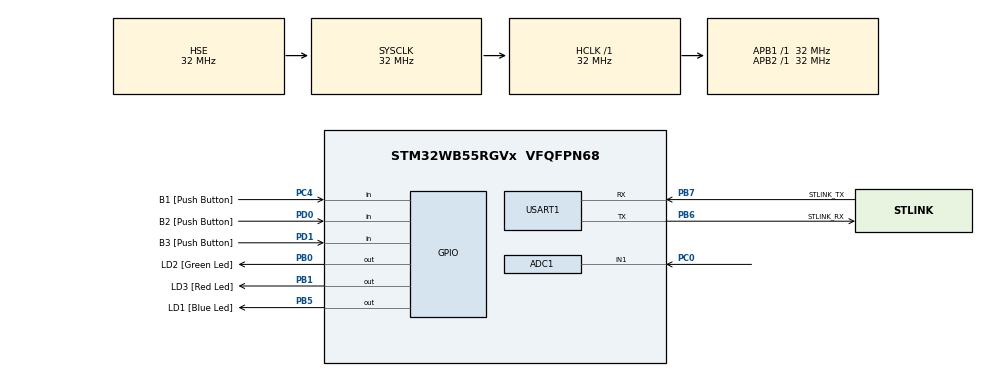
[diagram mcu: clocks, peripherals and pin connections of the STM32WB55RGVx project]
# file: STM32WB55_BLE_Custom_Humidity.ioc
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ADC1.Channel-0\#ChannelRegularConversion=ADC_CHANNEL_1
ADC1.NbrOfConversionFlag=1
ADC1.OffsetNumber-0\#ChannelRegularConversion=ADC_OFFSET_NONE
ADC1.Rank-0\#ChannelRegularConversion=1
ADC1.SamplingTime-0\#ChannelRegularConversion=ADC_SAMPLETIME_2CYCLES_5
ADC1.master=1
Mcu.Family=STM32WB
Mcu.Name=STM32WB55RGVx
Mcu.Package=VFQFPN68
NVIC.ADC1_IRQn=true\:0\:0\:false\:false\:true\:true\:true\:true
NVIC.HSEM_IRQn=true\:0\:0\:false\:false\:true\:false\:true\:true
NVIC.IPCC_C1_RX_IRQn=true\:0\:0\:false\:false\:true\:true\:true\:true
NVIC.IPCC_C1_TX_IRQn=true\:0\:0\:false\:false\:true\:true\:true\:true
NVIC.PriorityGroup=NVIC_PRIORITYGROUP_4
NVIC.RTC_WKUP_IRQn=true\:0\:0\:false\:false\:true\:true\:true\:true
NVIC.TIM1_UP_TIM16_IRQn=true\:0\:0\:false\:false\:true\:true\:true\:true
OSC_IN.Mode=HSE-External-Oscillator
OSC_IN.Signal=RCC_OSC_IN
OSC_OUT.Mode=HSE-External-Oscillator
OSC_OUT.Signal=RCC_OSC_OUT
PA11.Signal=USB_DM
PA12.Signal=USB_DP
PA13.GPIO_Label=JTMS
PA13.Mode=Trace_Asynchronous_SW
PA13.Signal=SYS_JTMS-SWDIO
PA14.GPIO_Label=JTCK
PA14.Mode=Trace_Asynchronous_SW
PA14.Signal=SYS_JTCK-SWCLK
PB0.GPIO_Label=LD2 [Green Led]
PB0.Signal=GPIO_Output
PB1.GPIO_Label=LD3 [Red Led]
PB1.Signal=GPIO_Output
PB3.GPIO_Label=JTDO
PB3.Mode=Trace_Asynchronous_SW
PB3.Signal=SYS_JTDO-SWO
PB5.GPIO_Label=LD1 [Blue Led]
PB5.Signal=GPIO_Output
PB6.GPIO_Label=STLINK_RX
PB6.GPIO_PuPd=GPIO_PULLUP
PB6.Mode=Asynchronous
PB6.Signal=USART1_TX
PB7.GPIO_Label=STLINK_TX
PB7.GPIO_PuPd=GPIO_PULLUP
PB7.Mode=Asynchronous
PB7.Signal=USART1_RX
PC0.Signal=ADCx_IN1
PC13.Mode=SYS_WakeUp1
PC13.Signal=SYS_WKUP2
PC14-OSC32_IN.Mode=LSE-External-Oscillator
PC14-OSC32_IN.Signal=RCC_OSC32_IN
PC15-OSC32_OUT.Mode=LSE-External-Oscillator
PC15-OSC32_OUT.Signal=RCC_OSC32_OUT
PC4.GPIO_Label=B1 [Push Button]
PC4.Signal=GPIO_Input
PD0.GPIO_Label=B2 [Push Button]
PD0.Signal=GPIO_Input
PD1.GPIO_Label=B3 [Push Button]
PD1.Signal=GPIO_Input
ProjectManager.HeapSize=0x400
ProjectManager.StackSize=0x1000
ProjectManager.TargetToolchain=STM32CubeIDE
RCC.ADCFreq_Value=48000000
RCC.AHBFreq_Value=32000000
RCC.APB1Freq_Value=32000000
RCC.APB1TimFreq_Value=32000000
RCC.APB2Freq_Value=32000000
RCC.APB2TimFreq_Value=32000000
RCC.APB3Freq_Value=16000000
RCC.CortexFreq_Value=32000000
RCC.HCLKFreq_Value=32000000
RCC.HSE_VALUE=32000000
RCC.HSI48_VALUE=48000000
RCC.HSI_VALUE=16000000
RCC.LSE_Drive_Capability=RCC_LSEDRIVE_LOW
RCC.PLLN=32
RCC.PLLSAI1N=24
RCC.RFWKPClockSelection=RCC_RFWKPCLKSOURCE_LSE
RCC.SMPSCLockSelectionVirtual=RCC_SMPSCLKSOURCE_HSE
RCC.SMPSCLockSelectionVirtualVirtual=RCC_SMPSCLKSOURCE_HSI
RCC.SMPSDivider=4
RCC.SYSCLKFreq_VALUE=32000000
RCC.SYSCLKSource=RCC_SYSCLKSOURCE_HSE
RCC.USBFreq_Value=48000000
RCC.VCOOutputFreq_Value=128000000
RF1.Mode=RF1_Activate
RF1.Signal=RF_RF1
SH.ADCx_IN1.0=ADC1_IN1,IN1-Single-Ended
STM32_WPAN.AD_SERVICE_CLASS_UUID_1=18 1A
STM32_WPAN.AD_SERVICE_CLASS_UUID_1_INV=[1A, 18]
STM32_WPAN.AD_TYPE_COMPLETE_LOCAL_NAME=MY_HUMI
STM32_WPAN.AD_TYPE_COMPLETE_LOCAL_NAME_LENGTH=8
STM32_WPAN.BLE_DBG_APP_EN=0
STM32_WPAN.CFG_DEBUG_APP_TRACE=1
STM32_WPAN.CFG_DEBUG_BLE_TRACE=1
STM32_WPAN.CFG_GAP_DEVICE_NAME=MY_HUMI
STM32_WPAN.CFG_GAP_DEVICE_NAME_LENGTH=7
STM32_WPAN.CFG_HW_USART1_ENABLED=1
STM32_WPAN.CUSTOM_P2P_SERVER=Disabled
STM32_WPAN.CUSTOM_TEMPLATE=Enabled
STM32_WPAN.INCLUDE_AD_TYPE_128_BIT_SERV_UUID_CMPLT_LIST=0
STM32_WPAN.INCLUDE_AD_TYPE_16_BIT_SERV_UUID_CMPLT_LIST=1
STM32_WPAN.INCLUDE_AD_TYPE_COMPLETE_LOCAL_NAME=1
STM32_WPAN.INCLUDE_AD_TYPE_MANUFACTURER_SPECIFIC_DATA=1
STM32_WPAN.INCLUDE_AD_TYPE_TX_POWER_LEVEL=1
STM32_WPAN.NUMBER_OF_SERVICES=1
STM32_WPAN.PAIRING_PARAMETERS=ON
STM32_WPAN.SERVICE1_CHAR1_ATTR_PERMISSION_AUTHEN_READ=\ 
STM32_WPAN.SERVICE1_CHAR1_GATT_NOTIFY_ATTRIBUTE_WRITE=\ 
STM32_WPAN.SERVICE1_CHAR1_GATT_NOTIFY_READ_REQ_AND_WAIT_FOR_APPL_RESP=GATT_NOTIFY_READ_REQ_AND_WAIT_FOR_APPL_RESP
STM32_WPAN.SERVICE1_CHAR1_GATT_NOTIFY_WRITE_REQ_AND_WAIT_FOR_APPL_RESP=\ 
STM32_WPAN.SERVICE1_CHAR1_LONG_NAME=My_Humidity_Char
STM32_WPAN.SERVICE1_CHAR1_PROP_READ=CHAR_PROP_READ
STM32_WPAN.SERVICE1_CHAR1_SHORT_NAME=HUM_C
STM32_WPAN.SERVICE1_CHAR1_UUID=2A 6F
STM32_WPAN.SERVICE1_CHAR1_UUID_TYPE=0x01
STM32_WPAN.SERVICE1_CHAR1_VALUE_LENGTH=1
STM32_WPAN.SERVICE1_LONG_NAME=My_Humidity_Server
STM32_WPAN.SERVICE1_SHORT_NAME=My_HS
STM32_WPAN.SERVICE1_UUID=18 1A
STM32_WPAN.SERVICE1_UUID_TYPE=0x01
TIM16.ClockDivision=TIM_CLOCKDIVISION_DIV1
TIM16.Period=1000 - 1
TIM16.Prescaler=32000 - 1
USART1.VirtualMode-Asynchronous=VM_ASYNC
USART1.WordLength=WORDLENGTH_7B
VP_HSEM_VS_HSEM.Mode=HSEM_Activate
VP_IPCC_VS_IPCC.Mode=IPCC_Activate
VP_MEMORYMAP_VS_MEMORYMAP.Mode=CurAppReg
VP_RTC_VS_RTC_Activate.Mode=RTC_Enabled
VP_RTC_VS_RTC_WakeUp_intern.Mode=WakeUp
VP_SEQUENCER_VS_SEQUENCER.Mode=SEQUENCER_Enabled
VP_STM32_WPAN_VS_BLE_HOST.Mode=STM32_WPAN_Enabled
VP_TIM16_VS_ClockSourceINT.Mode=Enable_Timer
VP_TINY_LPM_VS_TINY_LPM.Mode=TINY_LPM_Enabled
board=NUCLEO-WB55RG

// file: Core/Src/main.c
/* USER CODE BEGIN Header */
/**
  ******************************************************************************
  * @file           : main.c
  * @brief          : Main program body
  ******************************************************************************
  * @attention
  *
  * Copyright (c) 2023 STMicroelectronics.
  * All rights reserved.
  *
  * This software is licensed under terms that can be found in the LICENSE file
  * in the root directory of this software component.
  * If no LICENSE file comes with this software, it is provided AS-IS.
  *
  ******************************************************************************
  */
/* USER CODE END Header */
#include "main.h"

ADC_HandleTypeDef hadc1;

IPCC_HandleTypeDef hipcc;

RTC_HandleTypeDef hrtc;

TIM_HandleTypeDef htim16;

UART_HandleTypeDef huart1;

void SystemClock_Config(void);
void PeriphCommonClock_Config(void);
static void MX_GPIO_Init(void);
static void MX_IPCC_Init(void);
static void MX_RTC_Init(void);
static void MX_USART1_UART_Init(void);
static void MX_ADC1_Init(void);
static void MX_MEMORYMAP_Init(void);
static void MX_TIM16_Init(void);
static void MX_RF_Init(void);

/* USER CODE BEGIN 0 */
uint16_t AD_RES = 0;

/* USER CODE END 0 */

int main(void)
{

  /* MCU Configuration--------------------------------------------------------*/

  /* Reset of all peripherals, Initializes the Flash interface and the Systick. */
  HAL_Init();
  /* Config code for STM32_WPAN (HSE Tuning must be done before system clock configuration) */
  MX_APPE_Config();

  /* Configure the system clock */
  SystemClock_Config();

/* Configure the peripherals common clocks */
  PeriphCommonClock_Config();

  /* IPCC initialisation */
  MX_IPCC_Init();

  /* Initialize all configured peripherals */
  MX_GPIO_Init();
  MX_RTC_Init();
  MX_USART1_UART_Init();
  MX_ADC1_Init();
  MX_MEMORYMAP_Init();
  MX_TIM16_Init();
  MX_RF_Init();
  /* USER CODE BEGIN 2 */

  initBuffer();

  /* USER CODE END 2 */

  /* Init code for STM32_WPAN */
  MX_APPE_Init();

  /* Infinite loop */
  /* USER CODE BEGIN WHILE */
  HAL_TIM_Base_Start_IT(&htim16);
  while (1)
  {
    /* USER CODE END WHILE */
    MX_APPE_Process();

  }
}

void SystemClock_Config(void)
{
  RCC_OscInitTypeDef RCC_OscInitStruct = {0};
  RCC_ClkInitTypeDef RCC_ClkInitStruct = {0};

  /** Macro to configure the PLL multiplication factor
  */
  __HAL_RCC_PLL_PLLM_CONFIG(RCC_PLLM_DIV1);

  /** Macro to configure the PLL clock source
  */
  __HAL_RCC_PLL_PLLSOURCE_CONFIG(RCC_PLLSOURCE_MSI);

  /** Configure LSE Drive Capability
  */
  HAL_PWR_EnableBkUpAccess();
  __HAL_RCC_LSEDRIVE_CONFIG(RCC_LSEDRIVE_LOW);

  /** Configure the main internal regulator output voltage
  */
  __HAL_PWR_VOLTAGESCALING_CONFIG(PWR_REGULATOR_VOLTAGE_SCALE1);

  /** Initializes the RCC Oscillators according to the specified parameters
  * in the RCC_OscInitTypeDef structure.
  */
  RCC_OscInitStruct.OscillatorType = RCC_OSCILLATORTYPE_HSI|RCC_OSCILLATORTYPE_LSI1
                              |RCC_OSCILLATORTYPE_HSE|RCC_OSCILLATORTYPE_LSE
                              |RCC_OSCILLATORTYPE_MSI;
  RCC_OscInitStruct.HSEState = RCC_HSE_ON;
  RCC_OscInitStruct.LSEState = RCC_LSE_ON;
  RCC_OscInitStruct.HSIState = RCC_HSI_ON;
  RCC_OscInitStruct.MSIState = RCC_MSI_ON;
  RCC_OscInitStruct.HSICalibrationValue = RCC_HSICALIBRATION_DEFAULT;
  RCC_OscInitStruct.MSICalibrationValue = RCC_MSICALIBRATION_DEFAULT;
  RCC_OscInitStruct.MSIClockRange = RCC_MSIRANGE_6;
  RCC_OscInitStruct.LSIState = RCC_LSI_ON;
  RCC_OscInitStruct.PLL.PLLState = RCC_PLL_NONE;
  if (HAL_RCC_OscConfig(&RCC_OscInitStruct) != HAL_OK)
  {
    Error_Handler();
  }

  /** Configure the SYSCLKSource, HCLK, PCLK1 and PCLK2 clocks dividers
  */
  RCC_ClkInitStruct.ClockType = RCC_CLOCKTYPE_HCLK4|RCC_CLOCKTYPE_HCLK2
                              |RCC_CLOCKTYPE_HCLK|RCC_CLOCKTYPE_SYSCLK
                              |RCC_CLOCKTYPE_PCLK1|RCC_CLOCKTYPE_PCLK2;
  RCC_ClkInitStruct.SYSCLKSource = RCC_SYSCLKSOURCE_HSE;
  RCC_ClkInitStruct.AHBCLKDivider = RCC_SYSCLK_DIV1;
  RCC_ClkInitStruct.APB1CLKDivider = RCC_HCLK_DIV1;
  RCC_ClkInitStruct.APB2CLKDivider = RCC_HCLK_DIV1;
  RCC_ClkInitStruct.AHBCLK2Divider = RCC_SYSCLK_DIV1;
  RCC_ClkInitStruct.AHBCLK4Divider = RCC_SYSCLK_DIV1;

  if (HAL_RCC_ClockConfig(&RCC_ClkInitStruct, FLASH_LATENCY_1) != HAL_OK)
  {
    Error_Handler();
  }
}

void PeriphCommonClock_Config(void)
{
  RCC_PeriphCLKInitTypeDef PeriphClkInitStruct = {0};

  /** Initializes the peripherals clock
  */
  PeriphClkInitStruct.PeriphClockSelection = RCC_PERIPHCLK_SMPS|RCC_PERIPHCLK_RFWAKEUP;
  PeriphClkInitStruct.RFWakeUpClockSelection = RCC_RFWKPCLKSOURCE_LSE;
  PeriphClkInitStruct.SmpsClockSelection = RCC_SMPSCLKSOURCE_HSE;
  PeriphClkInitStruct.SmpsDivSelection = RCC_SMPSCLKDIV_RANGE1;

  if (HAL_RCCEx_PeriphCLKConfig(&PeriphClkInitStruct) != HAL_OK)
  {
    Error_Handler();
  }
}

static void MX_ADC1_Init(void)
{

  ADC_ChannelConfTypeDef sConfig = {0};

  /** Common config
  */
  hadc1.Instance = ADC1;
  hadc1.Init.ClockPrescaler = ADC_CLOCK_ASYNC_DIV1;
  hadc1.Init.Resolution = ADC_RESOLUTION_12B;
  hadc1.Init.DataAlign = ADC_DATAALIGN_RIGHT;
  hadc1.Init.ScanConvMode = ADC_SCAN_DISABLE;
  hadc1.Init.EOCSelection = ADC_EOC_SINGLE_CONV;
  hadc1.Init.LowPowerAutoWait = DISABLE;
  hadc1.Init.ContinuousConvMode = DISABLE;
  hadc1.Init.NbrOfConversion = 1;
  hadc1.Init.DiscontinuousConvMode = DISABLE;
  hadc1.Init.ExternalTrigConv = ADC_SOFTWARE_START;
  hadc1.Init.ExternalTrigConvEdge = ADC_EXTERNALTRIGCONVEDGE_NONE;
  hadc1.Init.DMAContinuousRequests = DISABLE;
  hadc1.Init.Overrun = ADC_OVR_DATA_PRESERVED;
  hadc1.Init.OversamplingMode = DISABLE;
  if (HAL_ADC_Init(&hadc1) != HAL_OK)
  {
    Error_Handler();
  }

  /** Configure Regular Channel
  */
  sConfig.Channel = ADC_CHANNEL_1;
  sConfig.Rank = ADC_REGULAR_RANK_1;
  sConfig.SamplingTime = ADC_SAMPLETIME_2CYCLES_5;
  sConfig.SingleDiff = ADC_SINGLE_ENDED;
  sConfig.OffsetNumber = ADC_OFFSET_NONE;
  sConfig.Offset = 0;
  if (HAL_ADC_ConfigChannel(&hadc1, &sConfig) != HAL_OK)
  {
    Error_Handler();
  }

}

static void MX_IPCC_Init(void)
{

  hipcc.Instance = IPCC;
  if (HAL_IPCC_Init(&hipcc) != HAL_OK)
  {
    Error_Handler();
  }

}

static void MX_MEMORYMAP_Init(void)
{

}

static void MX_RF_Init(void)
{

}

static void MX_RTC_Init(void)
{

  /** Initialize RTC Only
  */
  hrtc.Instance = RTC;
  hrtc.Init.HourFormat = RTC_HOURFORMAT_24;
  hrtc.Init.AsynchPrediv = CFG_RTC_ASYNCH_PRESCALER;
  hrtc.Init.SynchPrediv = CFG_RTC_SYNCH_PRESCALER;
  hrtc.Init.OutPut = RTC_OUTPUT_DISABLE;
  hrtc.Init.OutPutPolarity = RTC_OUTPUT_POLARITY_HIGH;
  hrtc.Init.OutPutType = RTC_OUTPUT_TYPE_OPENDRAIN;
  hrtc.Init.OutPutRemap = RTC_OUTPUT_REMAP_NONE;
  if (HAL_RTC_Init(&hrtc) != HAL_OK)
  {
    Error_Handler();
  }

  /** Enable the WakeUp
  */
  if (HAL_RTCEx_SetWakeUpTimer_IT(&hrtc, 0, RTC_WAKEUPCLOCK_RTCCLK_DIV16) != HAL_OK)
  {
    Error_Handler();
  }

}

static void MX_TIM16_Init(void)
{

  htim16.Instance = TIM16;
  htim16.Init.Prescaler = 32000 - 1;
  htim16.Init.CounterMode = TIM_COUNTERMODE_UP;
  htim16.Init.Period = 1000 - 1;
  htim16.Init.ClockDivision = TIM_CLOCKDIVISION_DIV1;
  htim16.Init.RepetitionCounter = 0;
  htim16.Init.AutoReloadPreload = TIM_AUTORELOAD_PRELOAD_DISABLE;
  if (HAL_TIM_Base_Init(&htim16) != HAL_OK)
  {
    Error_Handler();
  }

}

static void MX_USART1_UART_Init(void)
{

  huart1.Instance = USART1;
  huart1.Init.BaudRate = 115200;
  huart1.Init.WordLength = UART_WORDLENGTH_7B;
  huart1.Init.StopBits = UART_STOPBITS_1;
  huart1.Init.Parity = UART_PARITY_NONE;
  huart1.Init.Mode = UART_MODE_TX_RX;
  huart1.Init.HwFlowCtl = UART_HWCONTROL_NONE;
  huart1.Init.OverSampling = UART_OVERSAMPLING_16;
  huart1.Init.OneBitSampling = UART_ONE_BIT_SAMPLE_DISABLE;
  huart1.Init.ClockPrescaler = UART_PRESCALER_DIV1;
  huart1.AdvancedInit.AdvFeatureInit = UART_ADVFEATURE_NO_INIT;
  if (HAL_UART_Init(&huart1) != HAL_OK)
  {
    Error_Handler();
  }
  if (HAL_UARTEx_SetTxFifoThreshold(&huart1, UART_TXFIFO_THRESHOLD_1_8) != HAL_OK)
  {
    Error_Handler();
  }
  if (HAL_UARTEx_SetRxFifoThreshold(&huart1, UART_RXFIFO_THRESHOLD_1_8) != HAL_OK)
  {
    Error_Handler();
  }
  if (HAL_UARTEx_DisableFifoMode(&huart1) != HAL_OK)
  {
    Error_Handler();
  }

}

static void MX_GPIO_Init(void)
{
  GPIO_InitTypeDef GPIO_InitStruct = {0};

  /* GPIO Ports Clock Enable */
  __HAL_RCC_GPIOC_CLK_ENABLE();
  __HAL_RCC_GPIOB_CLK_ENABLE();
  __HAL_RCC_GPIOA_CLK_ENABLE();
  __HAL_RCC_GPIOD_CLK_ENABLE();

  /*Configure GPIO pin Output Level */
  HAL_GPIO_WritePin(GPIOB, LD2_Pin|LD3_Pin|LD1_Pin, GPIO_PIN_RESET);

  /*Configure GPIO pin : B1_Pin */
  GPIO_InitStruct.Pin = B1_Pin;
  GPIO_InitStruct.Mode = GPIO_MODE_INPUT;
  GPIO_InitStruct.Pull = GPIO_NOPULL;
  HAL_GPIO_Init(B1_GPIO_Port, &GPIO_InitStruct);

  /*Configure GPIO pins : LD2_Pin LD3_Pin LD1_Pin */
  GPIO_InitStruct.Pin = LD2_Pin|LD3_Pin|LD1_Pin;
  GPIO_InitStruct.Mode = GPIO_MODE_OUTPUT_PP;
  GPIO_InitStruct.Pull = GPIO_NOPULL;
  GPIO_InitStruct.Speed = GPIO_SPEED_FREQ_LOW;
  HAL_GPIO_Init(GPIOB, &GPIO_InitStruct);

  /*Configure GPIO pins : PA11 PA12 */
  GPIO_InitStruct.Pin = GPIO_PIN_11|GPIO_PIN_12;
  GPIO_InitStruct.Mode = GPIO_MODE_AF_PP;
  GPIO_InitStruct.Pull = GPIO_NOPULL;
  GPIO_InitStruct.Speed = GPIO_SPEED_FREQ_LOW;
  GPIO_InitStruct.Alternate = GPIO_AF10_USB;
  HAL_GPIO_Init(GPIOA, &GPIO_InitStruct);

  /*Configure GPIO pins : B2_Pin B3_Pin */
  GPIO_InitStruct.Pin = B2_Pin|B3_Pin;
  GPIO_InitStruct.Mode = GPIO_MODE_INPUT;
  GPIO_InitStruct.Pull = GPIO_NOPULL;
  HAL_GPIO_Init(GPIOD, &GPIO_InitStruct);

}

/* USER CODE BEGIN 4 */

// Callback: timer has rolled over
void HAL_TIM_PeriodElapsedCallback(TIM_HandleTypeDef *htim)
{
  // Check which version of the timer triggered this callback and toggle LED
  if (htim == &htim16 )
  {
    HAL_GPIO_TogglePin(GPIOB, GPIO_PIN_1);
    // Start ADC Conversion
    HAL_ADC_Start_IT(&hadc1);

  }
}

//void HAL_ADC_ConvCpltCallback(ADC_HandleTypeDef* hadc)
//{
    // Read & Update The ADC Result
//    AD_RES = HAL_ADC_GetValue(&hadc1);
//}

/* USER CODE END 4 */

void Error_Handler(void)
{
  __disable_irq();
  while (1)
  {
  }
}
